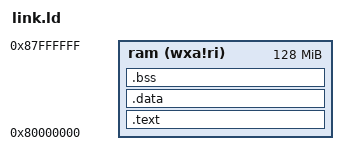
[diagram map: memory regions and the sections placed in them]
OUTPUT_ARCH( "riscv" )
ENTRY( _start )

MEMORY
{
  ram   (wxa!ri) : ORIGIN = 0x80000000, LENGTH = 128M
}

PHDRS
{
  text PT_LOAD;
  data PT_LOAD;
  bss PT_LOAD;
}

SECTIONS
{
  .text : {
    *(.text.start);
    PROVIDE(_text_start = .);
    *(.text.init) *(.text .text.*)
    PROVIDE(_text_end = .);
  } >ram AT>ram :text

  . = ALIGN(0x1000);
  etext = .;

  .data : {
    . = ALIGN(4096);
    PROVIDE(_data_start = .);
    *(.sdata .sdata.*) *(.data .data.*)
    PROVIDE(_data_end = .);
  } >ram AT>ram :data

  .bss :{
    PROVIDE(_bss_start = .);
    *(.sbss .sbss.*) *(.bss .bss.*)
    PROVIDE(_bss_end = .);
  } >ram AT>ram :bss

  PROVIDE(_memory_start = ORIGIN(ram));
  PROVIDE(_memory_end = ORIGIN(ram) + LENGTH(ram));

  /* reserve 0x16000 bytes for stack */
  . += 0x16000;
  stack_top = .;
  end = .;
  . += 0x200;
  _heap_start = .;

  PROVIDE(_heap_start = _bss_end);
  PROVIDE(_heap_size = _memory_end - _heap_start);
}
